# ESP32-S2-ULP register map
Vendor: ESPRESSIF SYSTEMS (SHANGHAI) CO., LTD.; Series: RISC-V ULP; File version: 2
32-bit RISC-V MCU
CPU: RV32IMC r0p0, little endian, no MPU, no FPU, 0 interrupt priority bits
Address unit: 32 bits
Registers are 32-bit, read-write, reset 0x0 unless marked. A register's access mark holds for its fields unless they carry their own. Offsets are from the block's base; lines under a group give offsets from that group; [hi:lo] are bit positions; {n}, {i} and the like mark numbered series; 'fields as' and 'values as' point back to an identical list; <NAME> marks a mode.

## Memory map
0x00008000 RTC_CNTL size 0x138 — Real-Time Clock Control
0x0000A400 RTC_IO size 0xF0 — Low-power Input/Output
0x0000C800 SENS size 0x110 — SENS Peripheral
0x0000EC00 RTC_I2C size 0x7C — Low-power I2C (Inter-Integrated Circuit) Controller

## Interrupts
0 TOUCH_DONE_INT (SENS)
1 TOUCH_INACTIVE_INT (SENS)
2 TOUCH_ACTIVE_INT (SENS)
3 SARADC1_DONE_INT (SENS)
4 SARADC2_DONE_INT (SENS)
5 TSENS_DONE_INT (SENS)
6 RISCV_START_INT (RTC_CNTL)
7 SW_INT (RTC_CNTL)
8 SWD_INT (RTC_CNTL)

## RTC_CNTL — Real-Time Clock Control
Base 0x00008000
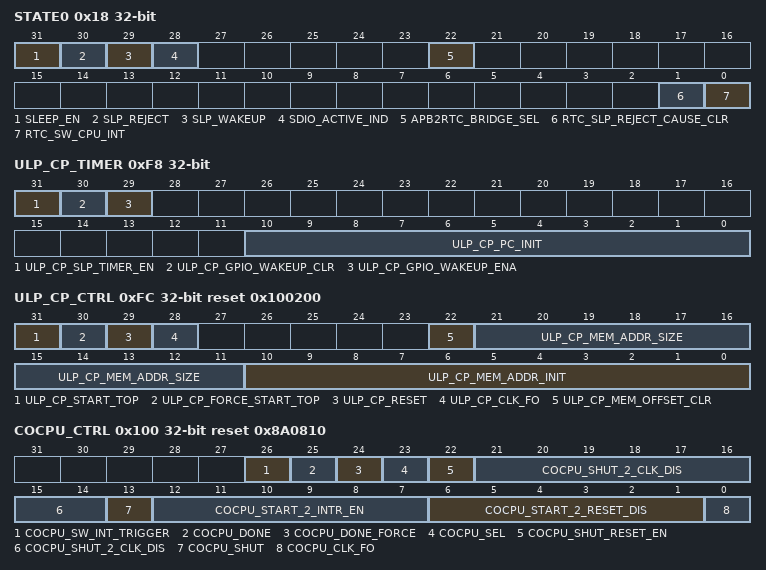
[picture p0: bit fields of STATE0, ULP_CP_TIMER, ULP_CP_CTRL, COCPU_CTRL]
0x18 STATE0 access per field — Configures the sleep / reject / wakeup state
  [31] SLEEP_EN rw — Sends the chip to sleep.
  [30] SLP_REJECT rw — Sleep reject bit.
  [29] SLP_WAKEUP rw — Sleep wakeup bit.
  [28] SDIO_ACTIVE_IND ro — Indicates the SDIO is active.
  [22] APB2RTC_BRIDGE_SEL rw — 1: APB to RTC using bridge 0: APB to RTC using sync
  [1] RTC_SLP_REJECT_CAUSE_CLR wo — Clears the RTC reject-to-sleep cause.
  [0] RTC_SW_CPU_INT wo — Sends a SW RTC interrupt to CPU.
0xF8 ULP_CP_TIMER access per field — Configure coprocessor timer
  [31] ULP_CP_SLP_TIMER_EN rw — ULP coprocessor timer enable bit. 0: Disable hardware Timer. 1: Enable hardware timer
  [30] ULP_CP_GPIO_WAKEUP_CLR wo — Disable the option of ULP coprocessor woken up by RTC GPIO
  [29] ULP_CP_GPIO_WAKEUP_ENA rw — Enable the option of ULP coprocessor woken up by RTC GPIO
  [10:0] ULP_CP_PC_INIT rw — ULP coprocessor PC initial address
0xFC ULP_CP_CTRL access per field reset 0x100200 — ULP-FSM configuration register
  [31] ULP_CP_START_TOP rw — Write 1 to start ULP-FSM
  [30] ULP_CP_FORCE_START_TOP rw — Write 1 to start ULP-FSM by software
  [29] ULP_CP_RESET rw — ULP-FSM clock software reset
  [28] ULP_CP_CLK_FO rw — ULP-FSM clock force on
  [22] ULP_CP_MEM_OFFSET_CLR wo
  [21:11] ULP_CP_MEM_ADDR_SIZE rw
  [10:0] ULP_CP_MEM_ADDR_INIT rw
0x100 COCPU_CTRL access per field reset 0x8A0810 — ULP-RISCV configuration register
  [26] COCPU_SW_INT_TRIGGER wo — Trigger ULP-RISCV register interrupt
  [25] COCPU_DONE rw — DONE signal. Write 1 to this bit, ULP-RISCV will go to HALT and the timer starts counting
  [24] COCPU_DONE_FORCE rw — 0: select ULP-FSM DONE signal. 1: select ULP-RISCV DONE signal
  [23] COCPU_SEL rw — 0: select ULP-RISCV. 1: select ULP-FSM
  [22] COCPU_SHUT_RESET_EN rw — This bit is used to reset ULP-RISCV
  [21:14] COCPU_SHUT_2_CLK_DIS rw — Time from shut down ULP-RISCV to disable clock
  [13] COCPU_SHUT rw — Shut down ULP-RISCV
  [12:7] COCPU_START_2_INTR_EN rw — Time from ULP-RISCV startup to send out RISCV_START_INT interrupt
  [6:1] COCPU_START_2_RESET_DIS rw — Time from ULP-RISCV startup to pull down reset
  [0] COCPU_CLK_FO rw — ULP-RISCV clock force on
0x130 ULP_CP_TIMER_1 reset 0xC800 — Configure sleep cycle of the timer
  [31:8] ULP_CP_TIMER_SLP_CYCLE — Set sleep cycles for ULP coprocessor timer

## Licence text in the file
Copyright 2025 Espressif Systems (Shanghai) PTE LTD Licensed under the Apache License, Version 2.0 (the "License"); you may not use this file except in compliance with the License. You may obtain a copy of the License at http://www.apache.org/licenses/LICENSE-2.0 Unless required by applicable law or agreed to in writing, software distributed under the License is distributed on an "AS IS" BASIS, WITHOUT WARRANTIES OR CONDITIONS OF ANY KIND, either express or implied. See the License for the specific language governing permissions and limitations under the License.
